VERSION ""

NS_ :

BS_:

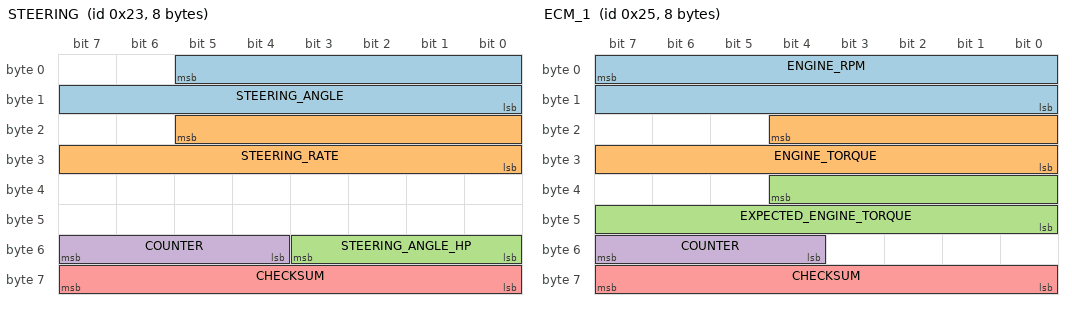
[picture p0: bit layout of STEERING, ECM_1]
BO_ 35 STEERING: 8 XXX
 SG_ STEERING_ANGLE : 5|14@0+ (0.5,-2048) [-2048|2047] "deg" XXX
 SG_ STEERING_RATE : 21|14@0+ (0.5,-2048) [-2048|2047] "deg/s" XXX
 SG_ STEERING_ANGLE_HP : 48|4@1+ (0.1,-0.4) [-0.4|0.4] "deg" XXX
 SG_ COUNTER : 55|4@0+ (1,0) [0|15] "" XXX
 SG_ CHECKSUM : 63|8@0+ (1,0) [0|255] "" XXX

BO_ 37 ECM_1: 8 XXX
 SG_ ENGINE_RPM : 7|16@0+ (1,0) [0|65535] "" XXX
 SG_ ENGINE_TORQUE : 20|13@0+ (0.25,-500) [-500|1547.5] "Nm" XXX
 SG_ EXPECTED_ENGINE_TORQUE : 36|13@0+ (0.25,-500) [-500|1547.5] "Nm" XXX
 SG_ COUNTER : 55|4@0+ (1,0) [0|15] "" XXX
 SG_ CHECKSUM : 63|8@0+ (1,0) [0|255] "" XXX

BO_ 181 ECM_TRQ: 8 XXX
 SG_ ENGINE_TORQ_MAX : 4|13@0+ (.25,-500) [-500|1547.5] "NM" XXX
 SG_ ENGINE_TORQ_MIN : 20|13@0+ (.25,-500) [-500|1547.5] "NM" XXX

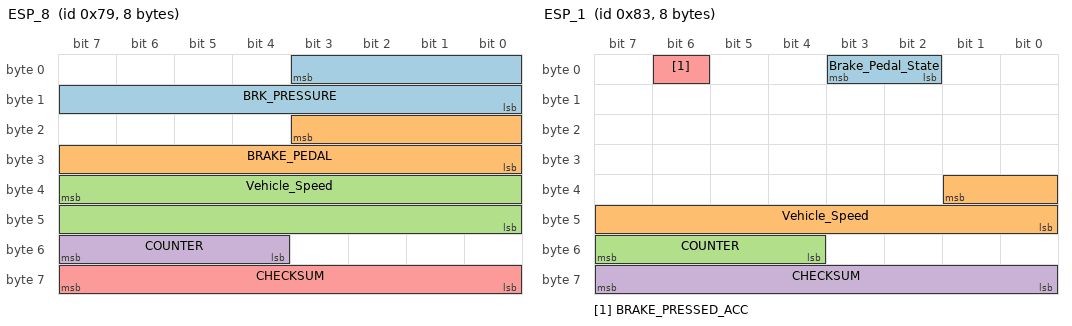
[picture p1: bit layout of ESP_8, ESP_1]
BO_ 121 ESP_8: 8 XXX
 SG_ BRK_PRESSURE : 3|12@0+ (1,0) [0|1] "" XXX
 SG_ BRAKE_PEDAL : 19|12@0+ (1,0) [0|1] "" XXX
 SG_ Vehicle_Speed : 39|16@0+ (0.0078125,0) [0|511.984375] "km/h" XXX
 SG_ COUNTER : 55|4@0+ (1,0) [0|15] "" XXX
 SG_ CHECKSUM : 63|8@0+ (1,0) [0|255] "" XXX

BO_ 131 ESP_1: 8 XXX
 SG_ Brake_Pedal_State : 2|2@1+ (1,0) [0|0] "" XXX
 SG_ Vehicle_Speed : 33|10@0+ (0.5,0) [0|511] "km/h" XXX
 SG_ COUNTER : 55|4@0+ (1,0) [0|15] "" XXX
 SG_ CHECKSUM : 63|8@0+ (1,0) [0|255] "" XXX
 SG_ BRAKE_PRESSED_ACC : 6|1@0+ (1,0) [0|3] "" XXX

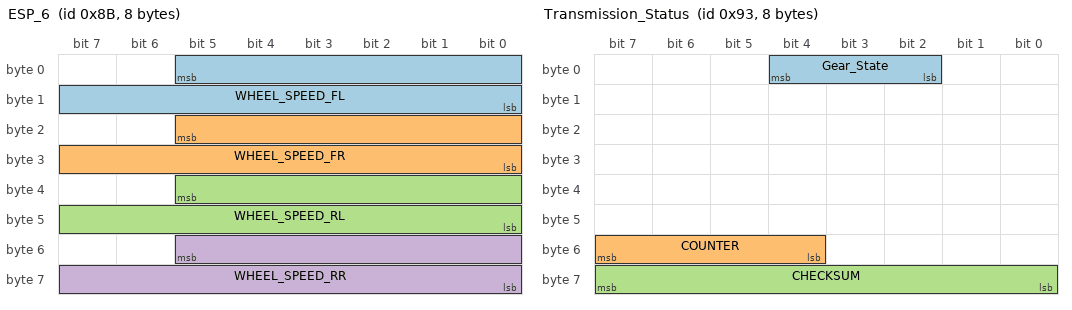
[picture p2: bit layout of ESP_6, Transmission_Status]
BO_ 139 ESP_6: 8 XXX
 SG_ WHEEL_SPEED_FL : 5|14@0+ (0.5,0) [0|8191] "rpm" XXX
 SG_ WHEEL_SPEED_FR : 21|14@0+ (0.5,0) [0|8191] "rpm" XXX
 SG_ WHEEL_SPEED_RL : 37|14@0+ (0.5,0) [0|8191] "rpm" XXX
 SG_ WHEEL_SPEED_RR : 53|14@0+ (0.5,0) [0|8191] "rpm" XXX

BO_ 147 Transmission_Status: 8 XXX
 SG_ Gear_State : 2|3@1+ (1,0) [0|15] "" XXX
 SG_ COUNTER : 55|4@0+ (1,0) [0|15] "" XXX
 SG_ CHECKSUM : 63|8@0+ (1,0) [0|255] "" XXX

BO_ 464 ORC_1: 8 XXX
 SG_ SEATBELT_DRIVER_UNLATCHED : 13|1@0+ (1,0) [0|1] "" XXX

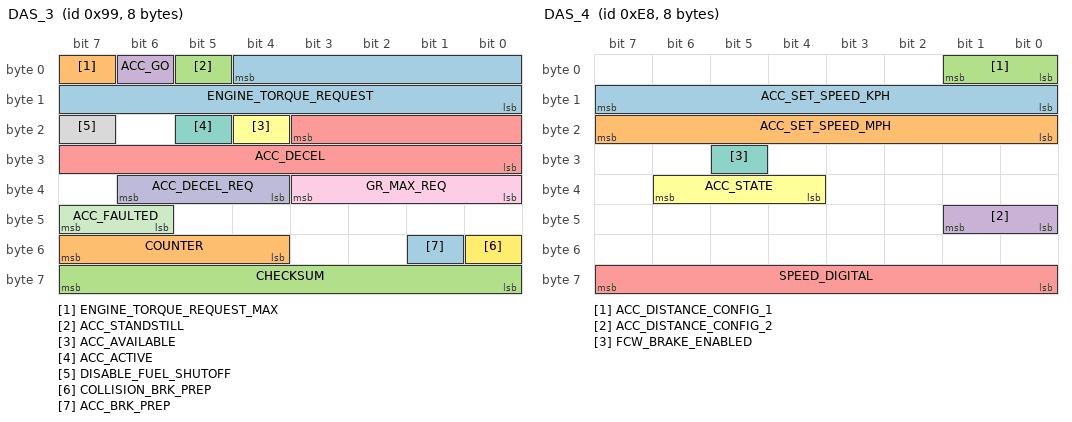
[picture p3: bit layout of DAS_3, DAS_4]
BO_ 153 DAS_3: 8 XXX
 SG_ ENGINE_TORQUE_REQUEST : 4|13@0+ (0.25,-500) [-500|1547.5] "Nm" XXX
 SG_ ENGINE_TORQUE_REQUEST_MAX : 7|1@0+ (1,0) [0|1] "" XXX
 SG_ ACC_STANDSTILL : 5|1@0+ (1,0) [0|1] ""  XXX
 SG_ ACC_GO : 6|1@1+ (1,0) [0|0] "" XXX
 SG_ ACC_DECEL : 19|12@0+ (0.004885,-16) [-16|4] "m/s2" XXX
 SG_ ACC_AVAILABLE : 20|1@0+ (1,0) [0|1] "" XXX
 SG_ ACC_ACTIVE : 21|1@0+ (1,0) [0|1] "" XXX
 SG_ DISABLE_FUEL_SHUTOFF : 23|1@1+ (1,0) [0|0] "" XXX
 SG_ GR_MAX_REQ : 32|4@1+ (1,0) [0|0] "" XXX
 SG_ ACC_DECEL_REQ : 36|3@1+ (1,0) [0|0] "" XXX
 SG_ ACC_FAULTED : 46|2@1+ (1,0) [0|0] "" XXX
 SG_ COLLISION_BRK_PREP : 48|1@1+ (1,0) [0|0] "" XXX
 SG_ ACC_BRK_PREP : 49|1@1+ (1,0) [0|0] "" XXX
 SG_ COUNTER : 55|4@0+ (1,0) [0|15] "" XXX
 SG_ CHECKSUM : 63|8@0+ (1,0) [0|255] "" XXX

BO_ 232 DAS_4: 8 XXX
 SG_ ACC_SET_SPEED_KPH : 15|8@0+ (1,0) [0|3] "km/h" XXX
 SG_ ACC_SET_SPEED_MPH : 23|8@0+ (1,0) [0|3] "mph" XXX
 SG_ ACC_DISTANCE_CONFIG_1 : 1|2@0+ (1,0) [0|3] "" XXX
 SG_ ACC_DISTANCE_CONFIG_2 : 41|2@0+ (1,0) [0|3] "" XXX
 SG_ SPEED_DIGITAL : 63|8@0+ (1,0) [0|255] "mph" XXX
 SG_ ACC_STATE : 38|3@0+ (1,0) [0|7] "" XXX
 SG_ FCW_BRAKE_ENABLED : 29|1@0+ (1,0) [0|1] "" XXX

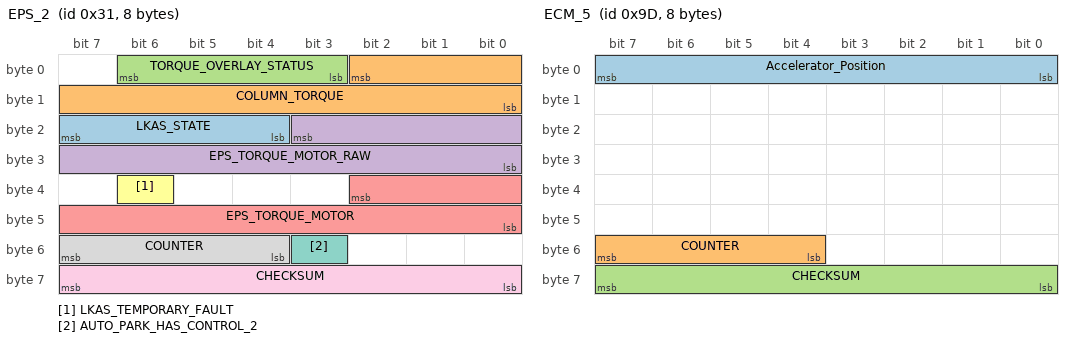
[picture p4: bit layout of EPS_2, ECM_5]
BO_ 49 EPS_2: 8 XXX
 SG_ LKAS_STATE : 23|4@0+ (1,0) [0|15] "" XXX
 SG_ COLUMN_TORQUE : 2|11@0+ (1,-1024) [-1024|1023] "" XXX
 SG_ TORQUE_OVERLAY_STATUS : 6|4@0+ (1,0) [0|15] "" XXX
 SG_ EPS_TORQUE_MOTOR_RAW : 19|12@0+ (1,-2048) [-2048|2047] "" XXX
 SG_ EPS_TORQUE_MOTOR : 34|11@0+ (1,-1024) [-1024|1023] "" XXX
 SG_ LKAS_TEMPORARY_FAULT : 38|1@0+ (1,0) [0|1] "" XXX
 SG_ AUTO_PARK_HAS_CONTROL_2 : 51|1@0+ (1,0) [0|1] "" XXX
 SG_ COUNTER : 55|4@0+ (1,0) [0|15] "" XXX
 SG_ CHECKSUM : 63|8@0+ (1,0) [0|255] "" XXX

BO_ 157 ECM_5: 8 XXX
 SG_ Accelerator_Position : 0|8@1+ (0.4,0) [0|100] "%" XXX
 SG_ COUNTER : 55|4@0+ (1,0) [0|15] "" XXX
 SG_ CHECKSUM : 63|8@0+ (1,0) [0|255] "" XXX

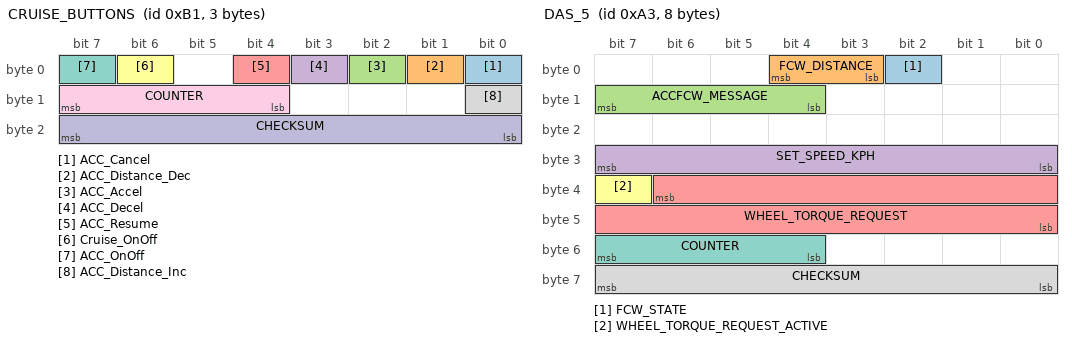
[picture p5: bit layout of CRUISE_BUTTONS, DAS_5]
BO_ 177 CRUISE_BUTTONS: 3 XXX
 SG_ ACC_Cancel : 0|1@1+ (1,0) [0|0] "" XXX
 SG_ ACC_Distance_Dec : 1|1@1+ (1,0) [0|0] "" XXX
 SG_ ACC_Accel : 2|1@1+ (1,0) [0|0] "" XXX
 SG_ ACC_Decel : 3|1@1+ (1,0) [0|0] "" XXX
 SG_ ACC_Resume : 4|1@0+ (1,0) [0|1] "" XXX
 SG_ Cruise_OnOff : 6|1@1+ (1,0) [0|0] "" XXX
 SG_ ACC_OnOff : 7|1@1+ (1,0) [0|0] "" XXX
 SG_ ACC_Distance_Inc : 8|1@1+ (1,0) [0|0] "" XXX
 SG_ COUNTER : 15|4@0+ (1,0) [0|15] "" XXX
 SG_ CHECKSUM : 23|8@0+ (1,0) [0|255] "" XXX

BO_ 163 DAS_5: 8 XXX
 SG_ FCW_STATE : 2|1@1+ (1,0) [0|0] ""  XXX
 SG_ FCW_DISTANCE : 3|2@1+ (1,0) [0|0] ""  XXX
 SG_ ACCFCW_MESSAGE : 12|4@1+ (1,0) [0|0] ""  XXX
 SG_ SET_SPEED_KPH : 24|8@1+ (1,0) [0|250] "km/h"  XXX
 SG_ WHEEL_TORQUE_REQUEST : 38|15@0+ (1,-7767) [-7767|24999] "Nm"  XXX
 SG_ WHEEL_TORQUE_REQUEST_ACTIVE : 39|1@1+ (1,0) [0|0] ""  XXX
 SG_ COUNTER : 55|4@0+ (1,0) [0|15] "" XXX
 SG_ CHECKSUM : 63|8@0+ (1,0) [0|255] "" XXX

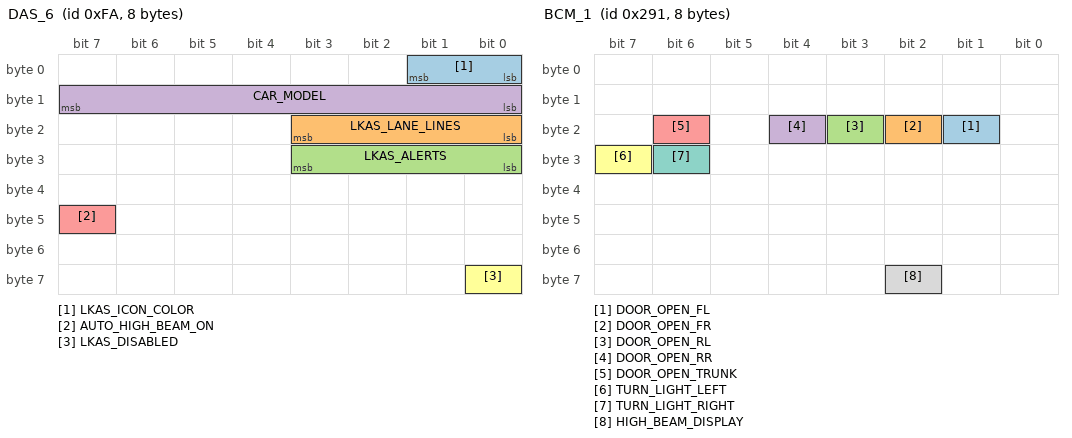
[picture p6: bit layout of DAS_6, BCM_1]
BO_ 250 DAS_6: 8 XXX
 SG_ LKAS_ICON_COLOR : 1|2@0+ (1,0) [0|3] "" XXX
 SG_ LKAS_LANE_LINES : 19|4@0+ (1,0) [0|1] "" XXX
 SG_ LKAS_ALERTS : 27|4@0+ (1,0) [0|1] "" XXX
 SG_ CAR_MODEL : 15|8@0+ (1,0) [0|255] "" XXX
 SG_ AUTO_HIGH_BEAM_ON : 47|1@1+ (1,0) [0|0] "" XXX
 SG_ LKAS_DISABLED : 56|1@1+ (1,0) [0|0] "" XXX

BO_ 720 BSM_1: 6 XXX
 SG_ RIGHT_STATUS : 5|1@0+ (1,0) [0|1] "" XXX
 SG_ LEFT_STATUS : 2|1@0+ (1,0) [0|1] "" XXX

BO_ 792 STEERING_LEVERS: 8 XXX
 SG_ TURN_SIGNALS : 0|2@1+ (1,0) [0|3] "" XXX
 SG_ HIGH_BEAM_PRESSED : 2|1@0+ (1,0) [0|3] "" XXX

BO_ 657 BCM_1: 8 XXX
 SG_ DOOR_OPEN_FL : 17|1@0+ (1,0) [0|1] "" XXX
 SG_ DOOR_OPEN_FR : 18|1@0+ (1,0) [0|1] "" XXX
 SG_ DOOR_OPEN_RL : 19|1@0+ (1,0) [0|1] "" XXX
 SG_ DOOR_OPEN_RR : 20|1@0+ (1,0) [0|1] "" XXX
 SG_ DOOR_OPEN_TRUNK : 22|1@0+ (1,0) [0|1] "" XXX
 SG_ TURN_LIGHT_LEFT : 31|1@0+ (1,0) [0|1] "" XXX
 SG_ TURN_LIGHT_RIGHT : 30|1@0+ (1,0) [0|1] "" XXX
 SG_ HIGH_BEAM_DISPLAY : 58|1@0+ (1,0) [0|1] "" XXX

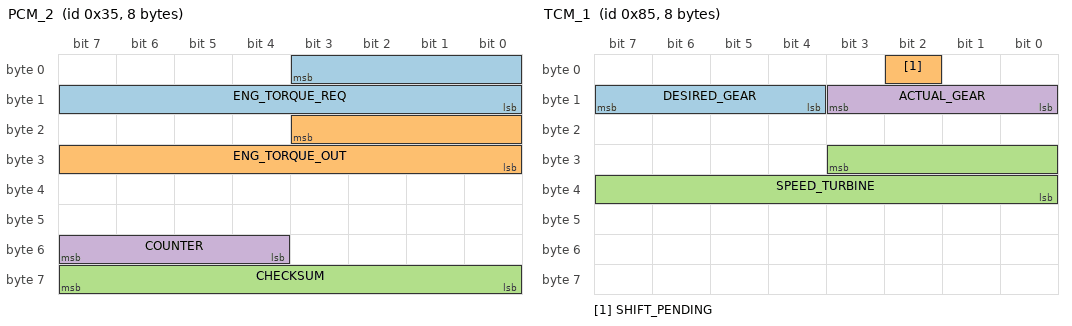
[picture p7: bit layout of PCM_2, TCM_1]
BO_ 53 PCM_2: 8 XXX
 SG_ ENG_TORQUE_REQ : 3|12@0+ (1,0) [0|7] "" XXX
 SG_ ENG_TORQUE_OUT : 19|12@0+ (1,0) [0|1] "" XXX
 SG_ CHECKSUM : 63|8@0+ (1,0) [0|255] "" XXX
 SG_ COUNTER : 55|4@0+ (1,0) [0|15] "" XXX

BO_ 133 TCM_1: 8 XXX
 SG_ DESIRED_GEAR : 15|4@0+ (1,0) [0|1] "" XXX
 SG_ SHIFT_PENDING : 2|1@0+ (1,0) [0|1] "" XXX
 SG_ SPEED_TURBINE : 27|12@0+ (0.04,0) [0|1] "km/h" XXX
 SG_ ACTUAL_GEAR : 11|4@0+ (1,0) [0|15] "" XXX

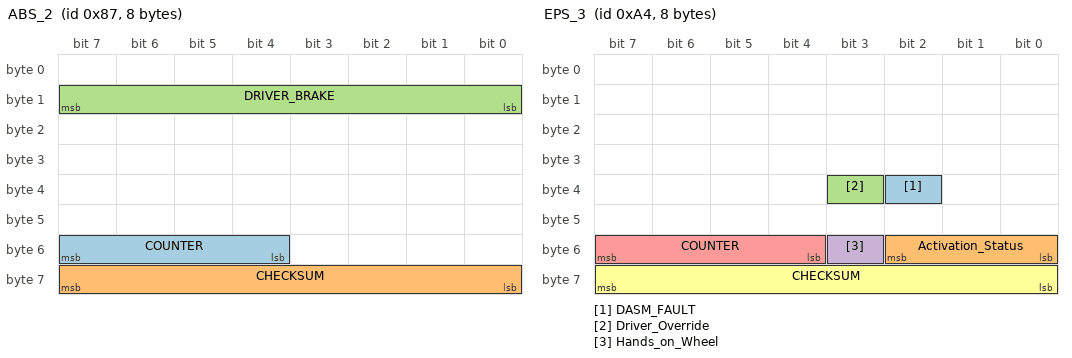
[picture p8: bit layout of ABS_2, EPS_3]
BO_ 135 ABS_2: 8 XXX
 SG_ COUNTER : 55|4@0+ (1,0) [0|1] "" XXX
 SG_ CHECKSUM : 63|8@0+ (1,0) [0|1] "" XXX
 SG_ DRIVER_BRAKE : 15|8@0+ (1,0) [0|1] "" XXX

BO_ 137 ESP_4: 8 XXX
 SG_ Yaw_Rate : 7|16@0+ (0.01,-327.68) [-327.68|327.66] "deg/s" XXX
 SG_ Acceleration : 32|8@1+ (0.08,-10.24) [-10.24|10.08] "m/s2" XXX

BO_ 164 EPS_3: 8 XXX
 SG_ DASM_FAULT : 34|1@0+ (1,0) [0|1] "" XXX
 SG_ Activation_Status : 48|3@1+ (1,0) [0|1] "" XXX
 SG_ Driver_Override : 35|1@0+ (1,0) [0|1] "" XXX
 SG_ Hands_on_Wheel : 51|1@0+ (1,0) [0|1] "" XXX
 SG_ COUNTER : 55|4@0+ (1,0) [0|15] "" XXX
 SG_ CHECKSUM : 63|8@0+ (1,0) [0|255] "" XXX

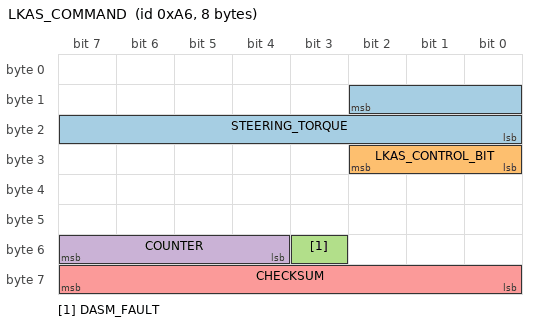
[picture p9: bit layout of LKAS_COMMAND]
BO_ 166 LKAS_COMMAND: 8 XXX
 SG_ STEERING_TORQUE : 10|11@0+ (1,-1024) [0|1] "" XXX
 SG_ LKAS_CONTROL_BIT : 24|3@1+ (1,0) [0|1] "" XXX
 SG_ DASM_FAULT : 51|1@0+ (1,0) [0|1] "" XXX
 SG_ COUNTER : 55|4@0+ (1,0) [0|15] "" XXX
 SG_ CHECKSUM : 63|8@0+ (1,0) [0|255] "" XXX

BO_ 221 Center_Stack_1: 8 XXX
 SG_ LKAS_Button : 53|1@1+ (1,0) [0|0] "" XXX
 SG_ Traction_Button : 54|1@0+ (1,0) [0|1] "" XXX

BO_ 650 Center_Stack_2: 8 XXX
 SG_ LKAS_Button : 57|1@1+ (1,0) [0|0] "" XXX

BU_: XXX

CM_ "AUTOGENERATED FILE, DO NOT EDIT";

CM_ "Imported file _comma.dbc starts here";
CM_ "Imported file _honda_common.dbc starts here";
CM_ SG_ 304 "Seems to be platform-agnostic";
CM_ SG_ 316 "Should exist on Nidec";
CM_ SG_ 420 BRAKE_HOLD_RELATED "On when Brake Hold engaged";
CM_ SG_ 490 LONG_ACCEL "wheel speed derivative, noisy and zero snapping";
CM_ SG_ 773 PASS_AIRBAG_ON "Might just be indicator light";
CM_ SG_ 773 PASS_AIRBAG_OFF "Might just be indicator light";
CM_ SG_ 780 CRUISE_SPEED "255 = no speed";
CM_ SG_ 780 PCM_SPEED "Used by Nidec";
CM_ SG_ 780 PCM_GAS "Used by Nidec";
CM_ SG_ 804 CRUISE_SPEED_PCM "255 = no speed";

CM_ "Imported file _nidec_common.dbc starts here";
CM_ SG_ 506 AEB_REQ_1 "set for duration of suspected AEB event";
CM_ SG_ 506 COMPUTER_BRAKE_ALT "Used by dual-can Nidec";
CM_ SG_ 506 BRAKE_PUMP_REQUEST_ALT "Used by dual-can Nidec";
CM_ SG_ 829 BEEP "beeps are pleasant, chimes are for warnngs etc...";

CM_ "Imported file _steering_sensors_b.dbc starts here";
CM_ "acura_rdx_2018_can.dbc starts here";

CM_ SG_ 422 PARKING_BRAKE_LIGHT "Believe this is just the dash light for the parking break";
